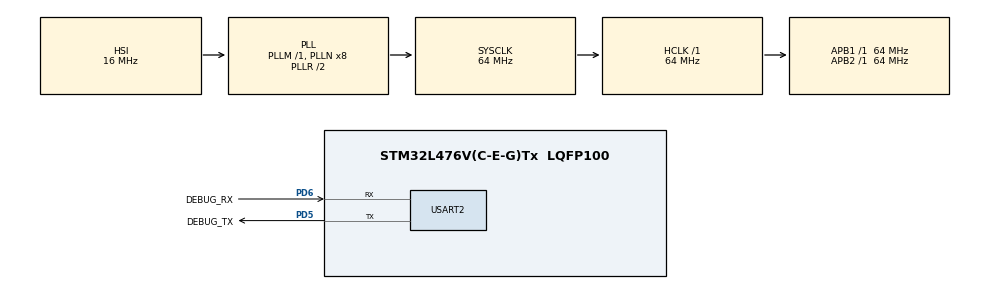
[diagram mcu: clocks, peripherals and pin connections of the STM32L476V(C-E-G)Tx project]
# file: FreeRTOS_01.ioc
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FREERTOS.Tasks01=Start,24,1024,MainThread,Default,NULL,Dynamic,NULL,NULL
FREERTOS.configTOTAL_HEAP_SIZE=6000
Mcu.Family=STM32L4
Mcu.Name=STM32L476V(C-E-G)Tx
Mcu.Package=LQFP100
NVIC.PriorityGroup=NVIC_PRIORITYGROUP_4
NVIC.TIM3_IRQn=true\:0\:0\:false\:false\:true\:false\:false\:true
NVIC.TimeBase=TIM3_IRQn
NVIC.TimeBaseIP=TIM3
PA13\ (JTMS-SWDIO).Mode=Serial_Wire
PA13\ (JTMS-SWDIO).Signal=SYS_JTMS-SWDIO
PA14\ (JTCK-SWCLK).Mode=Serial_Wire
PA14\ (JTCK-SWCLK).Signal=SYS_JTCK-SWCLK
PD5.GPIO_Label=DEBUG_TX
PD5.Mode=Asynchronous
PD5.Signal=USART2_TX
PD6.GPIO_Label=DEBUG_RX
PD6.Mode=Asynchronous
PD6.Signal=USART2_RX
ProjectManager.HeapSize=0x1000
ProjectManager.StackSize=0x2000
ProjectManager.TargetToolchain=STM32CubeIDE
RCC.ADCFreq_Value=64000000
RCC.AHBFreq_Value=64000000
RCC.APB1Freq_Value=64000000
RCC.APB1TimFreq_Value=64000000
RCC.APB2Freq_Value=64000000
RCC.APB2TimFreq_Value=64000000
RCC.CortexFreq_Value=64000000
RCC.HCLKFreq_Value=64000000
RCC.HSE_VALUE=8000000
RCC.HSI_VALUE=16000000
RCC.LSE_VALUE=32768
RCC.MSI_VALUE=4000000
RCC.PLLSourceVirtual=RCC_PLLSOURCE_HSI
RCC.SYSCLKFreq_VALUE=64000000
RCC.SYSCLKSource=RCC_SYSCLKSOURCE_PLLCLK
RCC.USBFreq_Value=64000000
RCC.VCOOutputFreq_Value=128000000
USART2.VirtualMode-Asynchronous=VM_ASYNC
VP_FREERTOS_VS_CMSIS_V2.Mode=CMSIS_V2
VP_SYS_VS_tim3.Mode=TIM3
board=custom

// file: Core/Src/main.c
/* USER CODE BEGIN Header */
/**
 ******************************************************************************
 * @file           : main.c
 * @brief          : Main program body
 ******************************************************************************
 * @attention
 *
 * <h2><center>&copy; Copyright (c) 2021 STMicroelectronics.
 * All rights reserved.</center></h2>
 *
 * This software component is licensed by ST under BSD 3-Clause license,
 * the "License"; You may not use this file except in compliance with the
 * License. You may obtain a copy of the License at:
 *                        opensource.org/licenses/BSD-3-Clause
 *
 ******************************************************************************
 */
/* USER CODE END Header */
#include "main.h"
#include "cmsis_os.h"

UART_HandleTypeDef huart2;

/* Definitions for Start */
osThreadId_t StartHandle;
const osThreadAttr_t Start_attributes = { .name = "Start", .priority =
		(osPriority_t) osPriorityNormal, .stack_size = 1024 * 4 };

void SystemClock_Config(void);
static void MX_GPIO_Init(void);
static void MX_USART2_UART_Init(void);
void MainThread(void *argument);

int main(void) {

	/* MCU Configuration--------------------------------------------------------*/

	/* Reset of all peripherals, Initializes the Flash interface and the Systick. */
	HAL_Init();

	/* Configure the system clock */
	SystemClock_Config();

	/* Initialize all configured peripherals */
	MX_GPIO_Init();
	MX_USART2_UART_Init();
	/* USER CODE BEGIN 2 */
	HAL_Delay(250);

	/* USER CODE END 2 */

	/* Init scheduler */
	osKernelInitialize();

	/* Create the thread(s) */
	/* creation of Start */
	StartHandle = osThreadNew(MainThread, NULL, &Start_attributes);
	if (StartHandle == NULL) {
		KERNEL_DBG("Failed to create the task");
	}

	/* Start scheduler */
	osKernelStart();

	/* We should never get here as control is now taken by the scheduler */
	/* Infinite loop */
	while (1) {

	}
}

void SystemClock_Config(void) {
	RCC_OscInitTypeDef RCC_OscInitStruct = { 0 };
	RCC_ClkInitTypeDef RCC_ClkInitStruct = { 0 };
	RCC_PeriphCLKInitTypeDef PeriphClkInit = { 0 };

	/** Initializes the RCC Oscillators according to the specified parameters
	 * in the RCC_OscInitTypeDef structure.
	 */
	RCC_OscInitStruct.OscillatorType = RCC_OSCILLATORTYPE_HSI;
	RCC_OscInitStruct.HSIState = RCC_HSI_ON;
	RCC_OscInitStruct.HSICalibrationValue = RCC_HSICALIBRATION_DEFAULT;
	RCC_OscInitStruct.PLL.PLLState = RCC_PLL_ON;
	RCC_OscInitStruct.PLL.PLLSource = RCC_PLLSOURCE_HSI;
	RCC_OscInitStruct.PLL.PLLM = 1;
	RCC_OscInitStruct.PLL.PLLN = 8;
	RCC_OscInitStruct.PLL.PLLP = RCC_PLLP_DIV7;
	RCC_OscInitStruct.PLL.PLLQ = RCC_PLLQ_DIV2;
	RCC_OscInitStruct.PLL.PLLR = RCC_PLLR_DIV2;
	if (HAL_RCC_OscConfig(&RCC_OscInitStruct) != HAL_OK) {
		Error_Handler();
	}
	/** Initializes the CPU, AHB and APB buses clocks
	 */
	RCC_ClkInitStruct.ClockType = RCC_CLOCKTYPE_HCLK | RCC_CLOCKTYPE_SYSCLK
			| RCC_CLOCKTYPE_PCLK1 | RCC_CLOCKTYPE_PCLK2;
	RCC_ClkInitStruct.SYSCLKSource = RCC_SYSCLKSOURCE_PLLCLK;
	RCC_ClkInitStruct.AHBCLKDivider = RCC_SYSCLK_DIV1;
	RCC_ClkInitStruct.APB1CLKDivider = RCC_HCLK_DIV1;
	RCC_ClkInitStruct.APB2CLKDivider = RCC_HCLK_DIV1;

	if (HAL_RCC_ClockConfig(&RCC_ClkInitStruct, FLASH_LATENCY_3) != HAL_OK) {
		Error_Handler();
	}
	PeriphClkInit.PeriphClockSelection = RCC_PERIPHCLK_USART2;
	PeriphClkInit.Usart2ClockSelection = RCC_USART2CLKSOURCE_PCLK1;
	if (HAL_RCCEx_PeriphCLKConfig(&PeriphClkInit) != HAL_OK) {
		Error_Handler();
	}
	/** Configure the main internal regulator output voltage
	 */
	if (HAL_PWREx_ControlVoltageScaling(PWR_REGULATOR_VOLTAGE_SCALE1)
			!= HAL_OK) {
		Error_Handler();
	}
}

static void MX_USART2_UART_Init(void) {

	huart2.Instance = USART2;
	huart2.Init.BaudRate = 115200;
	huart2.Init.WordLength = UART_WORDLENGTH_8B;
	huart2.Init.StopBits = UART_STOPBITS_1;
	huart2.Init.Parity = UART_PARITY_NONE;
	huart2.Init.Mode = UART_MODE_TX_RX;
	huart2.Init.HwFlowCtl = UART_HWCONTROL_NONE;
	huart2.Init.OverSampling = UART_OVERSAMPLING_16;
	huart2.Init.OneBitSampling = UART_ONE_BIT_SAMPLE_DISABLE;
	huart2.AdvancedInit.AdvFeatureInit = UART_ADVFEATURE_NO_INIT;
	if (HAL_UART_Init(&huart2) != HAL_OK) {
		Error_Handler();
	}

}

static void MX_GPIO_Init(void) {

	/* GPIO Ports Clock Enable */
	__HAL_RCC_GPIOA_CLK_ENABLE();
	__HAL_RCC_GPIOD_CLK_ENABLE();

}

void MainThread(void *argument) {
	/* USER CODE BEGIN 5 */
	UNUSED(argument);
	/* Infinite loop */
	for (;;) {
		KERNEL_DBG("MainThread is Running...");
		osDelay(250);
	}
	/* USER CODE END 5 */
}

void HAL_TIM_PeriodElapsedCallback(TIM_HandleTypeDef *htim) {
	if (htim->Instance == TIM3) {
		HAL_IncTick();
	}
}

void Error_Handler(void) {
	__disable_irq();
	while (1) {
	}
}

/************************ (C) COPYRIGHT STMicroelectronics *****END OF FILE****/
